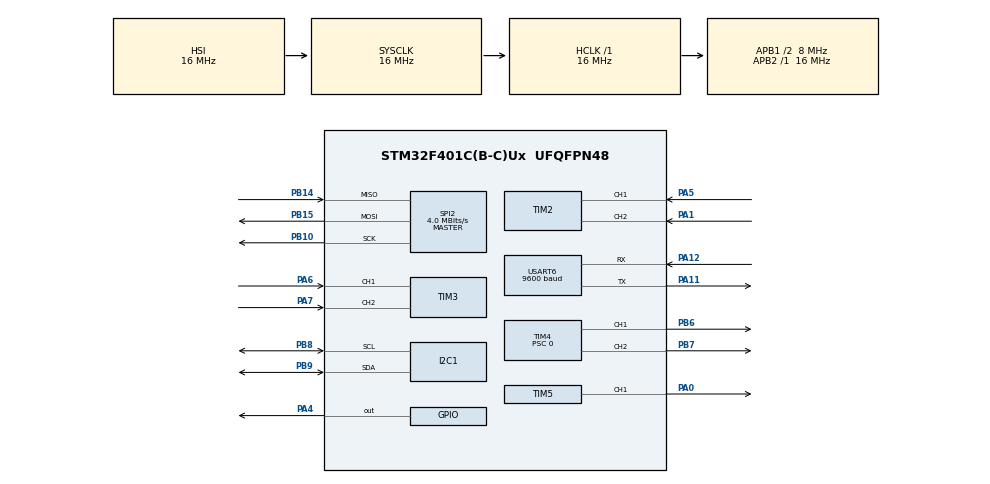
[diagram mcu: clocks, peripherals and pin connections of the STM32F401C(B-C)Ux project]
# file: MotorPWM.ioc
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Mcu.Family=STM32F4
Mcu.Name=STM32F401C(B-C)Ux
Mcu.Package=UFQFPN48
NVIC.PriorityGroup=NVIC_PRIORITYGROUP_4
NVIC.USART6_IRQn=true\:0\:0\:false\:false\:true\:true\:true\:true
PA0-WKUP.Signal=S_TIM5_CH1
PA1.Signal=S_TIM2_CH2
PA11.Mode=Asynchronous
PA11.Signal=USART6_TX
PA12.Mode=Asynchronous
PA12.Signal=USART6_RX
PA4.GPIO_ModeDefaultOutputPP=GPIO_MODE_OUTPUT_PP
PA4.GPIO_PuPd=GPIO_NOPULL
PA4.PinState=GPIO_PIN_SET
PA4.Signal=GPIO_Output
PA5.Signal=S_TIM2_CH1_ETR
PA6.Signal=S_TIM3_CH1
PA7.Signal=S_TIM3_CH2
PB10.Mode=Full_Duplex_Master
PB10.Signal=SPI2_SCK
PB14.Mode=Full_Duplex_Master
PB14.Signal=SPI2_MISO
PB15.Mode=Full_Duplex_Master
PB15.Signal=SPI2_MOSI
PB6.Signal=S_TIM4_CH1
PB7.Signal=S_TIM4_CH2
PB8.Mode=I2C
PB8.Signal=I2C1_SCL
PB9.Mode=I2C
PB9.Signal=I2C1_SDA
ProjectManager.HeapSize=0x200
ProjectManager.StackSize=0x400
ProjectManager.TargetToolchain=STM32CubeIDE
RCC.48MHZClocksFreq_Value=32000000
RCC.AHBFreq_Value=16000000
RCC.APB1CLKDivider=RCC_HCLK_DIV2
RCC.APB1Freq_Value=8000000
RCC.APB1TimFreq_Value=16000000
RCC.APB2Freq_Value=16000000
RCC.APB2TimFreq_Value=16000000
RCC.CortexFreq_Value=16000000
RCC.HCLKFreq_Value=16000000
RCC.HSE_VALUE=25000000
RCC.HSI_VALUE=16000000
RCC.LSE_VALUE=32768
RCC.PLLM=8
RCC.PLLN=64
RCC.SYSCLKFreq_VALUE=16000000
RCC.VCOOutputFreq_Value=128000000
SH.S_TIM2_CH1_ETR.0=TIM2_CH1,Encoder_Interface
SH.S_TIM2_CH2.0=TIM2_CH2,Encoder_Interface
SH.S_TIM3_CH1.0=TIM3_CH1,Encoder_Interface
SH.S_TIM3_CH2.0=TIM3_CH2,Encoder_Interface
SH.S_TIM4_CH1.0=TIM4_CH1,PWM Generation1 CH1
SH.S_TIM4_CH2.0=TIM4_CH2,PWM Generation2 CH2
SH.S_TIM5_CH1.0=TIM5_CH1,PWM Generation1 CH1
SPI2.CalculateBaudRate=4.0 MBits/s
SPI2.Direction=SPI_DIRECTION_2LINES
SPI2.Mode=SPI_MODE_MASTER
SPI2.VirtualType=VM_MASTER
TIM4.AutoReloadPreload=TIM_AUTORELOAD_PRELOAD_ENABLE
TIM4.Channel-PWM\ Generation1\ CH1=TIM_CHANNEL_1
TIM4.Channel-PWM\ Generation2\ CH2=TIM_CHANNEL_2
TIM4.Period=800
TIM4.Prescaler=0
TIM4.Pulse-PWM\ Generation1\ CH1=400
TIM4.Pulse-PWM\ Generation2\ CH2=600
TIM5.Channel-PWM\ Generation1\ CH1=TIM_CHANNEL_1
USART6.BaudRate=9600
USART6.VirtualMode=VM_ASYNC
VP_TIM4_VS_ClockSourceINT.Mode=Internal
VP_TIM5_VS_ClockSourceINT.Mode=Internal
board=custom

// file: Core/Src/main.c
/* USER CODE BEGIN Header */
/**
  ******************************************************************************
  * @file           : main.c
  * @brief          : Main program body
  ******************************************************************************
  * @attention
  *
  * Copyright (c) 2025 STMicroelectronics.
  * All rights reserved.
  *
  * This software is licensed under terms that can be found in the LICENSE file
  * in the root directory of this software component.
  * If no LICENSE file comes with this software, it is provided AS-IS.
  *
  ******************************************************************************
  */
/* USER CODE END Header */
#include "main.h"

/* USER CODE BEGIN Includes */
#include "OPERATION_Layer/OP_Header_Main.h"
/* USER CODE END Includes */

I2C_HandleTypeDef hi2c1;

SPI_HandleTypeDef hspi2;

TIM_HandleTypeDef htim2;
TIM_HandleTypeDef htim3;
TIM_HandleTypeDef htim4;
TIM_HandleTypeDef htim5;

UART_HandleTypeDef huart6;

void SystemClock_Config(void);
static void MX_GPIO_Init(void);
static void MX_TIM4_Init(void);
static void MX_TIM2_Init(void);
static void MX_I2C1_Init(void);
static void MX_SPI2_Init(void);
static void MX_TIM3_Init(void);
static void MX_USART6_UART_Init(void);
static void MX_TIM5_Init(void);

int main(void)
{

  /* MCU Configuration--------------------------------------------------------*/

  /* Reset of all peripherals, Initializes the Flash interface and the Systick. */
  HAL_Init();

  /* Configure the system clock */
  SystemClock_Config();

  /* Initialize all configured peripherals */
  MX_GPIO_Init();
  MX_TIM4_Init();
  MX_TIM2_Init();
  MX_I2C1_Init();
  MX_SPI2_Init();
  MX_TIM3_Init();
  MX_USART6_UART_Init();
  MX_TIM5_Init();
  /* USER CODE BEGIN 2 */
  HAL_TIM_PWM_Start(&htim4, TIM_CHANNEL_1);
  HAL_TIM_PWM_Start(&htim4, TIM_CHANNEL_2);
  /* USER CODE END 2 */

  /* Infinite loop */
  while (1)
  {

    /* USER CODE BEGIN 3 */
	ProcessMain();

  }
  /* USER CODE END 3 */
}

void SystemClock_Config(void)
{
  RCC_OscInitTypeDef RCC_OscInitStruct = {0};
  RCC_ClkInitTypeDef RCC_ClkInitStruct = {0};

  /** Configure the main internal regulator output voltage
  */
  __HAL_RCC_PWR_CLK_ENABLE();
  __HAL_PWR_VOLTAGESCALING_CONFIG(PWR_REGULATOR_VOLTAGE_SCALE2);

  /** Initializes the RCC Oscillators according to the specified parameters
  * in the RCC_OscInitTypeDef structure.
  */
  RCC_OscInitStruct.OscillatorType = RCC_OSCILLATORTYPE_HSI;
  RCC_OscInitStruct.HSIState = RCC_HSI_ON;
  RCC_OscInitStruct.HSICalibrationValue = RCC_HSICALIBRATION_DEFAULT;
  RCC_OscInitStruct.PLL.PLLState = RCC_PLL_NONE;
  if (HAL_RCC_OscConfig(&RCC_OscInitStruct) != HAL_OK)
  {
    Error_Handler();
  }

  /** Initializes the CPU, AHB and APB buses clocks
  */
  RCC_ClkInitStruct.ClockType = RCC_CLOCKTYPE_HCLK|RCC_CLOCKTYPE_SYSCLK
                              |RCC_CLOCKTYPE_PCLK1|RCC_CLOCKTYPE_PCLK2;
  RCC_ClkInitStruct.SYSCLKSource = RCC_SYSCLKSOURCE_HSI;
  RCC_ClkInitStruct.AHBCLKDivider = RCC_SYSCLK_DIV1;
  RCC_ClkInitStruct.APB1CLKDivider = RCC_HCLK_DIV2;
  RCC_ClkInitStruct.APB2CLKDivider = RCC_HCLK_DIV1;

  if (HAL_RCC_ClockConfig(&RCC_ClkInitStruct, FLASH_LATENCY_0) != HAL_OK)
  {
    Error_Handler();
  }
}

static void MX_I2C1_Init(void)
{

  hi2c1.Instance = I2C1;
  hi2c1.Init.ClockSpeed = 100000;
  hi2c1.Init.DutyCycle = I2C_DUTYCYCLE_2;
  hi2c1.Init.OwnAddress1 = 0;
  hi2c1.Init.AddressingMode = I2C_ADDRESSINGMODE_7BIT;
  hi2c1.Init.DualAddressMode = I2C_DUALADDRESS_DISABLE;
  hi2c1.Init.OwnAddress2 = 0;
  hi2c1.Init.GeneralCallMode = I2C_GENERALCALL_DISABLE;
  hi2c1.Init.NoStretchMode = I2C_NOSTRETCH_DISABLE;
  if (HAL_I2C_Init(&hi2c1) != HAL_OK)
  {
    Error_Handler();
  }

}

static void MX_SPI2_Init(void)
{

  /* SPI2 parameter configuration*/
  hspi2.Instance = SPI2;
  hspi2.Init.Mode = SPI_MODE_MASTER;
  hspi2.Init.Direction = SPI_DIRECTION_2LINES;
  hspi2.Init.DataSize = SPI_DATASIZE_8BIT;
  hspi2.Init.CLKPolarity = SPI_POLARITY_LOW;
  hspi2.Init.CLKPhase = SPI_PHASE_1EDGE;
  hspi2.Init.NSS = SPI_NSS_SOFT;
  hspi2.Init.BaudRatePrescaler = SPI_BAUDRATEPRESCALER_2;
  hspi2.Init.FirstBit = SPI_FIRSTBIT_MSB;
  hspi2.Init.TIMode = SPI_TIMODE_DISABLE;
  hspi2.Init.CRCCalculation = SPI_CRCCALCULATION_DISABLE;
  hspi2.Init.CRCPolynomial = 10;
  if (HAL_SPI_Init(&hspi2) != HAL_OK)
  {
    Error_Handler();
  }

}

static void MX_TIM2_Init(void)
{

  TIM_Encoder_InitTypeDef sConfig = {0};
  TIM_MasterConfigTypeDef sMasterConfig = {0};

  htim2.Instance = TIM2;
  htim2.Init.Prescaler = 0;
  htim2.Init.CounterMode = TIM_COUNTERMODE_UP;
  htim2.Init.Period = 4294967295;
  htim2.Init.ClockDivision = TIM_CLOCKDIVISION_DIV1;
  htim2.Init.AutoReloadPreload = TIM_AUTORELOAD_PRELOAD_DISABLE;
  sConfig.EncoderMode = TIM_ENCODERMODE_TI1;
  sConfig.IC1Polarity = TIM_ICPOLARITY_RISING;
  sConfig.IC1Selection = TIM_ICSELECTION_DIRECTTI;
  sConfig.IC1Prescaler = TIM_ICPSC_DIV1;
  sConfig.IC1Filter = 0;
  sConfig.IC2Polarity = TIM_ICPOLARITY_RISING;
  sConfig.IC2Selection = TIM_ICSELECTION_DIRECTTI;
  sConfig.IC2Prescaler = TIM_ICPSC_DIV1;
  sConfig.IC2Filter = 0;
  if (HAL_TIM_Encoder_Init(&htim2, &sConfig) != HAL_OK)
  {
    Error_Handler();
  }
  sMasterConfig.MasterOutputTrigger = TIM_TRGO_RESET;
  sMasterConfig.MasterSlaveMode = TIM_MASTERSLAVEMODE_DISABLE;
  if (HAL_TIMEx_MasterConfigSynchronization(&htim2, &sMasterConfig) != HAL_OK)
  {
    Error_Handler();
  }

}

static void MX_TIM3_Init(void)
{

  TIM_Encoder_InitTypeDef sConfig = {0};
  TIM_MasterConfigTypeDef sMasterConfig = {0};

  htim3.Instance = TIM3;
  htim3.Init.Prescaler = 0;
  htim3.Init.CounterMode = TIM_COUNTERMODE_UP;
  htim3.Init.Period = 65535;
  htim3.Init.ClockDivision = TIM_CLOCKDIVISION_DIV1;
  htim3.Init.AutoReloadPreload = TIM_AUTORELOAD_PRELOAD_DISABLE;
  sConfig.EncoderMode = TIM_ENCODERMODE_TI1;
  sConfig.IC1Polarity = TIM_ICPOLARITY_RISING;
  sConfig.IC1Selection = TIM_ICSELECTION_DIRECTTI;
  sConfig.IC1Prescaler = TIM_ICPSC_DIV1;
  sConfig.IC1Filter = 0;
  sConfig.IC2Polarity = TIM_ICPOLARITY_RISING;
  sConfig.IC2Selection = TIM_ICSELECTION_DIRECTTI;
  sConfig.IC2Prescaler = TIM_ICPSC_DIV1;
  sConfig.IC2Filter = 0;
  if (HAL_TIM_Encoder_Init(&htim3, &sConfig) != HAL_OK)
  {
    Error_Handler();
  }
  sMasterConfig.MasterOutputTrigger = TIM_TRGO_RESET;
  sMasterConfig.MasterSlaveMode = TIM_MASTERSLAVEMODE_DISABLE;
  if (HAL_TIMEx_MasterConfigSynchronization(&htim3, &sMasterConfig) != HAL_OK)
  {
    Error_Handler();
  }

}

static void MX_TIM4_Init(void)
{

  TIM_ClockConfigTypeDef sClockSourceConfig = {0};
  TIM_MasterConfigTypeDef sMasterConfig = {0};
  TIM_OC_InitTypeDef sConfigOC = {0};

  htim4.Instance = TIM4;
  htim4.Init.Prescaler = 0;
  htim4.Init.CounterMode = TIM_COUNTERMODE_UP;
  htim4.Init.Period = 800;
  htim4.Init.ClockDivision = TIM_CLOCKDIVISION_DIV1;
  htim4.Init.AutoReloadPreload = TIM_AUTORELOAD_PRELOAD_ENABLE;
  if (HAL_TIM_Base_Init(&htim4) != HAL_OK)
  {
    Error_Handler();
  }
  sClockSourceConfig.ClockSource = TIM_CLOCKSOURCE_INTERNAL;
  if (HAL_TIM_ConfigClockSource(&htim4, &sClockSourceConfig) != HAL_OK)
  {
    Error_Handler();
  }
  if (HAL_TIM_PWM_Init(&htim4) != HAL_OK)
  {
    Error_Handler();
  }
  sMasterConfig.MasterOutputTrigger = TIM_TRGO_RESET;
  sMasterConfig.MasterSlaveMode = TIM_MASTERSLAVEMODE_DISABLE;
  if (HAL_TIMEx_MasterConfigSynchronization(&htim4, &sMasterConfig) != HAL_OK)
  {
    Error_Handler();
  }
  sConfigOC.OCMode = TIM_OCMODE_PWM1;
  sConfigOC.Pulse = 400;
  sConfigOC.OCPolarity = TIM_OCPOLARITY_HIGH;
  sConfigOC.OCFastMode = TIM_OCFAST_DISABLE;
  if (HAL_TIM_PWM_ConfigChannel(&htim4, &sConfigOC, TIM_CHANNEL_1) != HAL_OK)
  {
    Error_Handler();
  }
  sConfigOC.Pulse = 600;
  if (HAL_TIM_PWM_ConfigChannel(&htim4, &sConfigOC, TIM_CHANNEL_2) != HAL_OK)
  {
    Error_Handler();
  }
  HAL_TIM_MspPostInit(&htim4);

}

static void MX_TIM5_Init(void)
{

  TIM_ClockConfigTypeDef sClockSourceConfig = {0};
  TIM_MasterConfigTypeDef sMasterConfig = {0};
  TIM_OC_InitTypeDef sConfigOC = {0};

  htim5.Instance = TIM5;
  htim5.Init.Prescaler = 0;
  htim5.Init.CounterMode = TIM_COUNTERMODE_UP;
  htim5.Init.Period = 4294967295;
  htim5.Init.ClockDivision = TIM_CLOCKDIVISION_DIV1;
  htim5.Init.AutoReloadPreload = TIM_AUTORELOAD_PRELOAD_DISABLE;
  if (HAL_TIM_Base_Init(&htim5) != HAL_OK)
  {
    Error_Handler();
  }
  sClockSourceConfig.ClockSource = TIM_CLOCKSOURCE_INTERNAL;
  if (HAL_TIM_ConfigClockSource(&htim5, &sClockSourceConfig) != HAL_OK)
  {
    Error_Handler();
  }
  if (HAL_TIM_PWM_Init(&htim5) != HAL_OK)
  {
    Error_Handler();
  }
  sMasterConfig.MasterOutputTrigger = TIM_TRGO_RESET;
  sMasterConfig.MasterSlaveMode = TIM_MASTERSLAVEMODE_DISABLE;
  if (HAL_TIMEx_MasterConfigSynchronization(&htim5, &sMasterConfig) != HAL_OK)
  {
    Error_Handler();
  }
  sConfigOC.OCMode = TIM_OCMODE_PWM1;
  sConfigOC.Pulse = 0;
  sConfigOC.OCPolarity = TIM_OCPOLARITY_HIGH;
  sConfigOC.OCFastMode = TIM_OCFAST_DISABLE;
  if (HAL_TIM_PWM_ConfigChannel(&htim5, &sConfigOC, TIM_CHANNEL_1) != HAL_OK)
  {
    Error_Handler();
  }
  HAL_TIM_MspPostInit(&htim5);

}

static void MX_USART6_UART_Init(void)
{

  huart6.Instance = USART6;
  huart6.Init.BaudRate = 9600;
  huart6.Init.WordLength = UART_WORDLENGTH_8B;
  huart6.Init.StopBits = UART_STOPBITS_1;
  huart6.Init.Parity = UART_PARITY_NONE;
  huart6.Init.Mode = UART_MODE_TX_RX;
  huart6.Init.HwFlowCtl = UART_HWCONTROL_NONE;
  huart6.Init.OverSampling = UART_OVERSAMPLING_16;
  if (HAL_UART_Init(&huart6) != HAL_OK)
  {
    Error_Handler();
  }

}

static void MX_GPIO_Init(void)
{
  GPIO_InitTypeDef GPIO_InitStruct = {0};

  /* GPIO Ports Clock Enable */
  __HAL_RCC_GPIOA_CLK_ENABLE();
  __HAL_RCC_GPIOB_CLK_ENABLE();

  /*Configure GPIO pin Output Level */
  HAL_GPIO_WritePin(GPIOA, GPIO_PIN_4, GPIO_PIN_SET);

  /*Configure GPIO pin : PA4 */
  GPIO_InitStruct.Pin = GPIO_PIN_4;
  GPIO_InitStruct.Mode = GPIO_MODE_OUTPUT_PP;
  GPIO_InitStruct.Pull = GPIO_NOPULL;
  GPIO_InitStruct.Speed = GPIO_SPEED_FREQ_LOW;
  HAL_GPIO_Init(GPIOA, &GPIO_InitStruct);

}

void Error_Handler(void)
{
  __disable_irq();
  while (1)
  {
  }
}
